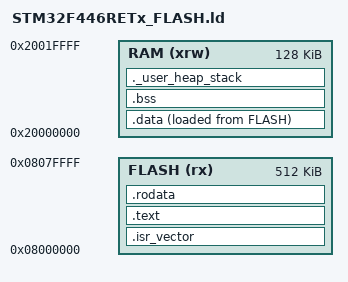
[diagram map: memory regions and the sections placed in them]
/* Linker script for STM32F446RETx (512K Flash, 128K SRAM) */

MEMORY
{
    RAM (xrw) : ORIGIN = 0x20000000, LENGTH = 128K
    FLASH (rx) : ORIGIN = 0x08000000, LENGTH = 512K
}

ENTRY(Reset_Handler)

SECTIONS
{
    .isr_vector :
    {
        . = ALIGN(4);
        KEEP(*(.isr_vector))
        . = ALIGN(4);
    } > FLASH

    .text :
    {
        . = ALIGN(4);
        *(.text)
        *(.text*)
        *(.glue_7)
        *(.glue_7t)
        *(.eh_frame)
        KEEP(*(.init))
        KEEP(*(.fini))
        . = ALIGN(4);
        _etext = .;
    } > FLASH

    .rodata :
    {
        . = ALIGN(4);
        *(.rodata)
        *(.rodata*)
        . = ALIGN(4);
    } > FLASH

    _sidata = LOADADDR(.data);

    .data :
    {
        . = ALIGN(4);
        _sdata = .;
        *(.data)
        *(.data*)
        . = ALIGN(4);
        _edata = .;
    } > RAM AT> FLASH

    .bss :
    {
        . = ALIGN(4);
        _sbss = .;
        __bss_start__ = _sbss;
        *(.bss)
        *(.bss*)
        *(COMMON)
        . = ALIGN(4);
        _ebss = .;
        __bss_end__ = _ebss;
    } > RAM

    ._user_heap_stack :
    {
        . = ALIGN(8);
        PROVIDE(end = .);
        PROVIDE(_end = .);
        . = . + 0x400;
        . = ALIGN(8);
    } > RAM

    /DISCARD/ :
    {
    }

    .ARM.attributes 0 : { *(.ARM.attributes) }
}

_estack = ORIGIN(RAM) + LENGTH(RAM);
